# STM32MP25_CM33 register map
File version: 1.3
CPU: CM33 r0p1, little endian, MPU, FPU, vendor SysTick, 8 interrupt priority bits
Registers are 32-bit, read-write, reset 0x0 unless marked. A register's access mark holds for its fields unless they carry their own. Offsets are from the block's base; [hi:lo] are bit positions.

## IWDG1 — IWDG address block description
Base 0x44010000
Same registers: IWDG2 0x44020000, IWDG3 0x44030000, IWDG4 0x44040000, IWDG5 0x46090000, IWDG1_S 0x54010000, IWDG2_S 0x54020000, IWDG3_S 0x54030000, IWDG4_S 0x54040000, IWDG5_S 0x56090000
0x00 IWDG_KR wo — IWDG key register
  [15:0] KEY — Key value (write only, read 0x0000) These bits can be used for several functions, depending upon the value written by the application: - 0xAAAA: reloads the RL[11:0] value into the IWDCNT down-counter (watchdog refresh), and write-protects registers. This value must be written by software at regular intervals, otherwise the watchdog generates a reset when the counter reaches 0. - 0x5555: enables write-accesses to the registers. - 0xCCCC: enables the watchdog (except if the hardware watchdog option is selected) and write-protects registers. - values different from 0x5555: write-protects registers. Note that only IWDG_PR, IWDG_RLR, IWDG_EWCR and IWDG_WINR registers have a write-protection mechanism.
0x04 IWDG_PR reset 0xF — IWDG prescaler register
  [3:0] PR — Prescaler divider These bits are write access protected, see Section71.4.6. They are written by software to select the prescaler divider feeding the counter clock. PVU bit of the IWDG status register (IWDG_SR) must be reset to be able to change the prescaler divider. Others: divider / 1024 Note: Reading this register returns the prescaler value from the VsubDD/sub voltage domain. This value may not be up to date/valid if a write operation to this register is ongoing. For this reason the value read from this register is valid only when the PVU bit in the IWDG status register (IWDG_SR) is reset.
    0=divider / 4; 1=divider / 8; 2=divider / 16; 3=divider / 32; 4=divider / 64; 5=divider / 128; 6=divider / 256; 7=divider / 512
0x08 IWDG_RLR reset 0xFFF — IWDG reload register
  [11:0] RL — Watchdog counter reload value These bits are write access protected, see Section71.4.6. They are written by software to define the value to be loaded in the watchdog counter each time the value 0xAAAA is written in the IWDG key register (IWDG_KR). The watchdog counter counts down from this value. The timeout period is a function of this value and the prescaler.clock. It is not recommended to set RL[11:0] to a value lower than 2. The RVU bit in the IWDG status register (IWDG_SR) must be reset to be able to change the reload value. Note: Reading this register returns the reload value from the VsubDD/sub voltage domain. This value may not be up to date/valid if a write operation to this register is ongoing, hence the value read from this register is valid only when the RVU bit in the IWDG status register (IWDG_SR) is reset.
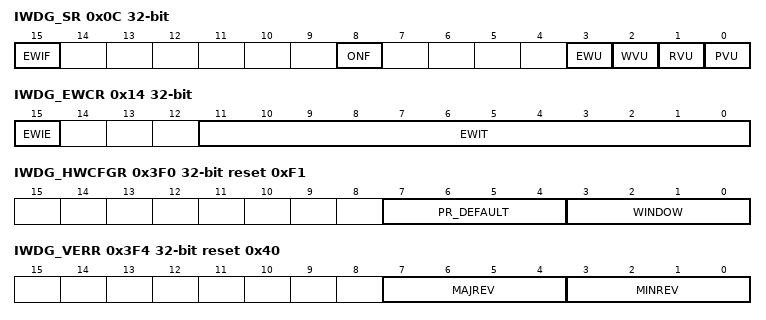
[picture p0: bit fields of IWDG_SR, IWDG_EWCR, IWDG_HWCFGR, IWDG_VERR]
0x0C IWDG_SR ro — IWDG status register
  [15] EWIF — Watchdog early interrupt flag This bit is set to ‘1’ by hardware in order to indicate that an early interrupt is pending. This bit must be cleared by the software by writing the bit EWIC of IWDG_ICR register to ‘1’.
  [8] ONF — Watchdog enable status bit Set to ‘1’ by hardware as soon as the IWDG is started. In software mode, it remains to '1' until the IWDG is reset. In hardware mode, this bit is always set to '1'.
    0=The IWDG is not activated; 1=The IWDG is activated and needs to be refreshed regularly by the application
  [3] EWU — Watchdog interrupt comparator value update This bit is set by hardware to indicate that an update of the interrupt comparator value (EWIT[11:0]) or an update of the EWIE is ongoing. It is reset by hardware when the update operation is completed in the VsubDD/sub voltage domain (takes up to one period of presc_ck and two periods of the IWDG kernel clock iwdg_ker_ck). The EWIT[11:0] and EWIE fields can be updated only when EWU bit is reset.
  [2] WVU — Watchdog counter window value update This bit is set by hardware to indicate that an update of the window value is ongoing. It is reset by hardware when the reload value update operation is completed in the VsubDD/sub voltage domain (takes up to one period of presc_ck and two periods of the IWDG kernel clock iwdg_ker_ck). The window value can be updated only when WVU bit is reset. This bit is generated only if generic “window” = 1.
  [1] RVU — Watchdog counter reload value update This bit is set by hardware to indicate that an update of the reload value is ongoing. It is reset by hardware when the reload value update operation is completed in the VsubDD/sub voltage domain (takes up to six periods of the IWDG kernel clock iwdg_ker_ck). The reload value can be updated only when RVU bit is reset.
  [0] PVU — Watchdog prescaler value update This bit is set by hardware to indicate that an update of the prescaler value is ongoing. It is reset by hardware when the prescaler update operation is completed in the VsubDD/sub voltage domain (takes up to six periods of the IWDG kernel clock iwdg_ker_ck). The prescaler value can be updated only when PVU bit is reset.
0x10 IWDG_WINR reset 0xFFF — IWDG window register
  [11:0] WIN — Watchdog counter window value These bits are write access protected, see Section71.4.6.They contain the high limit of the window value to be compared with the downcounter. To prevent a reset, the IWDCNT downcounter must be reloaded when its value is lower than WIN[11:0]+1 and greater than 1. The WVU bit in the IWDG status register (IWDG_SR) must be reset to be able to change the reload value. Note: Reading this register returns the reload value from the VsubDD/sub voltage domain. This value may not be valid if a write operation to this register is ongoing. For this reason the value read from this register is valid only when the WVU bit in the IWDG status register (IWDG_SR) is reset.
0x14 IWDG_EWCR — IWDG early wake-up interrupt register
  [15] EWIE — Watchdog early interrupt enable Set and reset by software. The EWU bit in the IWDG status register (IWDG_SR) must be reset to be able to change the value of this bit.
    0=The early interrupt interface is disabled; 1=The early interrupt interface is enabled
  [11:0] EWIT — Watchdog counter window value These bits are write access protected (see Section71.4.6). They are written by software to define at which position of the IWDCNT down-counter the early wake-up interrupt must be generated. The early interrupt is generated when the IWDCNT is lower or equal to EWIT[11:0]-1. EWIT[11:0] must be bigger than 1. An interrupt is generated only if EWIE = 1. The EWU bit in the IWDG status register (IWDG_SR) must be reset to be able to change the reload value. Note: Reading this register returns the Early wake-up comparator value and the Interrupt enable bit from the VsubDD/sub voltage domain. This value may not be up to date/valid if a write operation to this register is ongoing, hence the value read from this register is valid only when the EWU bit in the IWDG status register (IWDG_SR) is reset.
0x18 IWDG_ICR — IWDG interrupt clear register
  [15] EWIC — Watchdog early interrupt acknowledge The software must write a 1 into this bit in order to acknowledge the early wake-up interrupt and to clear the EWIF flag. Writing 0 has not effect, reading this flag returns a 0.
0x3F0 IWDG_HWCFGR ro reset 0xF1 — IWDG hardware configuration register
  [7:4] PR_DEFAULT — Prescaler default value This bit field gives the default value of the prescaler (see PR[3:0]: Prescaler divider of IWDG prescaler register (IWDG_PR) 1xxx: Prescaler (PR[3:0]) default value after reset is 1000
    0=Prescaler (PR[3:0]) default value after reset is 0000’; 1=Prescaler (PR[3:0]) default value after reset is 0001’; 2=Prescaler (PR[3:0]) default value after reset is 0010’; 3=Prescaler (PR[3:0]) default value after reset is 0011’; 4=Prescaler (PR[3:0]) default value after reset is 0100’; 5=Prescaler (PR[3:0]) default value after reset is 0101’; 6=Prescaler (PR[3:0]) default value after reset is 0110’; 7=Prescaler (PR[3:0]) default value after reset is 0111’
  [3:0] WINDOW — Support of Window function Others: Reserved
    0=Window option disabled; 1=Window option enabled
0x3F4 IWDG_VERR ro reset 0x40 — IWDG version register
  [7:4] MAJREV — IWDG major revision
  [3:0] MINREV — IWDG minor revision
0x3F8 IWDG_IDR ro reset 0x120041 — IWDG identification register
  [31:0] ID — IWDG identifier
0x3FC IWDG_SIDR ro reset 0xA3C5DD01 — IWDG size identification register
  [31:0] SID — IWDG size identifier The address decoding range is 1 Kbyte.
